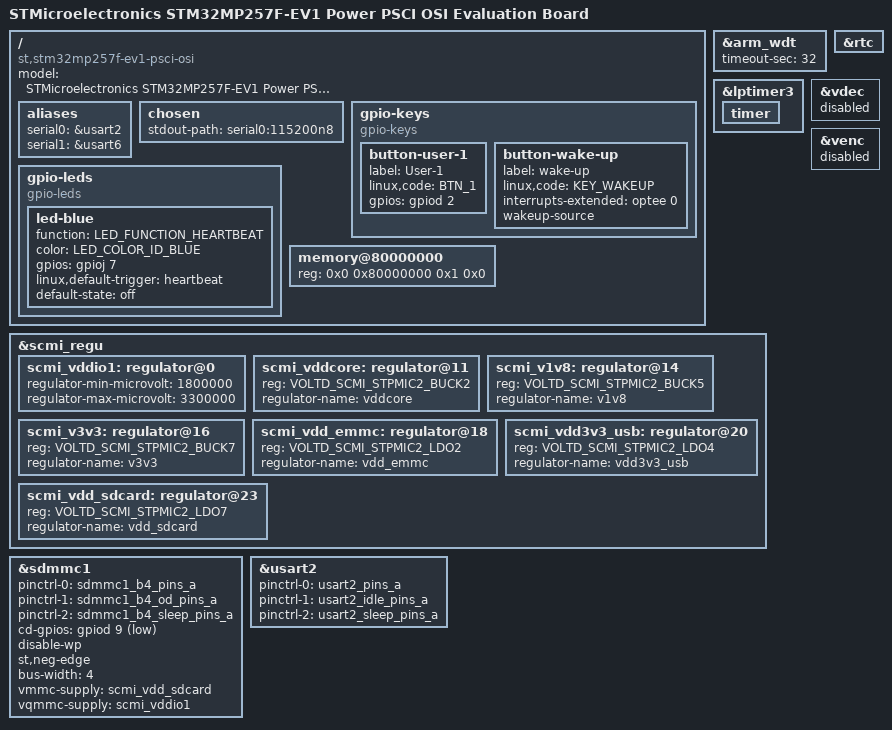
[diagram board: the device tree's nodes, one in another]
// SPDX-License-Identifier: (GPL-2.0-only OR BSD-3-Clause)
/*
 * Copyright (C) STMicroelectronics 2024 - All Rights Reserved
 */

/dts-v1/;

#include <dt-bindings/gpio/gpio.h>
#include <dt-bindings/input/input.h>
#include <dt-bindings/leds/common.h>
#include <dt-bindings/regulator/st,stm32mp25-regulator.h>
#include "stm32mp257.dtsi"
#include "stm32mp25xf.dtsi"
#include "stm32mp25-pinctrl.dtsi"
#include "stm32mp25xxai-pinctrl.dtsi"
#include "stm32mp257f-ev1-ca35tdcid-resmem.dtsi"

/ {
	model = "STMicroelectronics STM32MP257F-EV1 Power PSCI OSI Evaluation Board";
	compatible = "st,stm32mp257f-ev1-psci-osi", "st,stm32mp257f-ev1", "st,stm32mp257";

	aliases {
		serial0 = &usart2;
		serial1 = &usart6;
	};

	chosen {
		stdout-path = "serial0:115200n8";
	};

	gpio-keys {
		compatible = "gpio-keys";

		button-user-1 {
			label = "User-1";
			linux,code = <BTN_1>;
			gpios = <&gpiod 2 GPIO_ACTIVE_HIGH>;
			status = "okay";
		};

                /* use GPIO button for wakeup of Stop modes */
		button-wake-up {
			label = "wake-up";
			linux,code = <KEY_WAKEUP>;
			interrupts-extended = <&optee 0>;
			wakeup-source;
			status = "okay";
		};
	};

	gpio-leds {
		compatible = "gpio-leds";

		led-blue {
			function = LED_FUNCTION_HEARTBEAT;
			color = <LED_COLOR_ID_BLUE>;
			gpios = <&gpioj 7 GPIO_ACTIVE_HIGH>;
			linux,default-trigger = "heartbeat";
			default-state = "off";
		};
	};

	memory@80000000 {
		device_type = "memory";
		reg = <0x0 0x80000000 0x1 0x0>;
	};
};

&arm_wdt {
	timeout-sec = <32>;
	status = "okay";
};

/* use LPTIMER with tick broadcast for suspend mode */
&lptimer3 {
	status = "okay";
	timer {
		status = "okay";
	};
};

&rtc {
	status = "okay";
};

&scmi_regu {
	scmi_vddio1: regulator@0 {
		regulator-min-microvolt = <1800000>;
		regulator-max-microvolt = <3300000>;
	};
	scmi_vddcore: regulator@11  {
		reg = <VOLTD_SCMI_STPMIC2_BUCK2>;
		regulator-name = "vddcore";
	};
	scmi_v1v8: regulator@14  {
		reg = <VOLTD_SCMI_STPMIC2_BUCK5>;
		regulator-name = "v1v8";
	};
	scmi_v3v3: regulator@16 {
		reg = <VOLTD_SCMI_STPMIC2_BUCK7>;
		regulator-name = "v3v3";
	};
	scmi_vdd_emmc: regulator@18 {
		reg = <VOLTD_SCMI_STPMIC2_LDO2>;
		regulator-name = "vdd_emmc";
	};
	scmi_vdd3v3_usb: regulator@20 {
		reg = <VOLTD_SCMI_STPMIC2_LDO4>;
		regulator-name = "vdd3v3_usb";
	};
	scmi_vdd_sdcard: regulator@23 {
		reg = <VOLTD_SCMI_STPMIC2_LDO7>;
		regulator-name = "vdd_sdcard";
	};
};

&sdmmc1 {
	pinctrl-names = "default", "opendrain", "sleep";
	pinctrl-0 = <&sdmmc1_b4_pins_a>;
	pinctrl-1 = <&sdmmc1_b4_od_pins_a>;
	pinctrl-2 = <&sdmmc1_b4_sleep_pins_a>;
	cd-gpios = <&gpiod 9 (GPIO_ACTIVE_LOW | GPIO_PULL_UP)>;
	disable-wp;
	st,neg-edge;
	bus-width = <4>;
	vmmc-supply = <&scmi_vdd_sdcard>;
	vqmmc-supply = <&scmi_vddio1>;
	status = "okay";
};

&usart2 {
	pinctrl-names = "default", "idle", "sleep";
	pinctrl-0 = <&usart2_pins_a>;
	pinctrl-1 = <&usart2_idle_pins_a>;
	pinctrl-2 = <&usart2_sleep_pins_a>;
	/delete-property/dmas;
	/delete-property/dma-names;
        /* TEMP: waiting pm runtime and wake up support */
	/delete-property/power-domains;
	status = "okay";
};

&vdec {
	status = "disabled";
};

&venc {
	status = "disabled";
};
